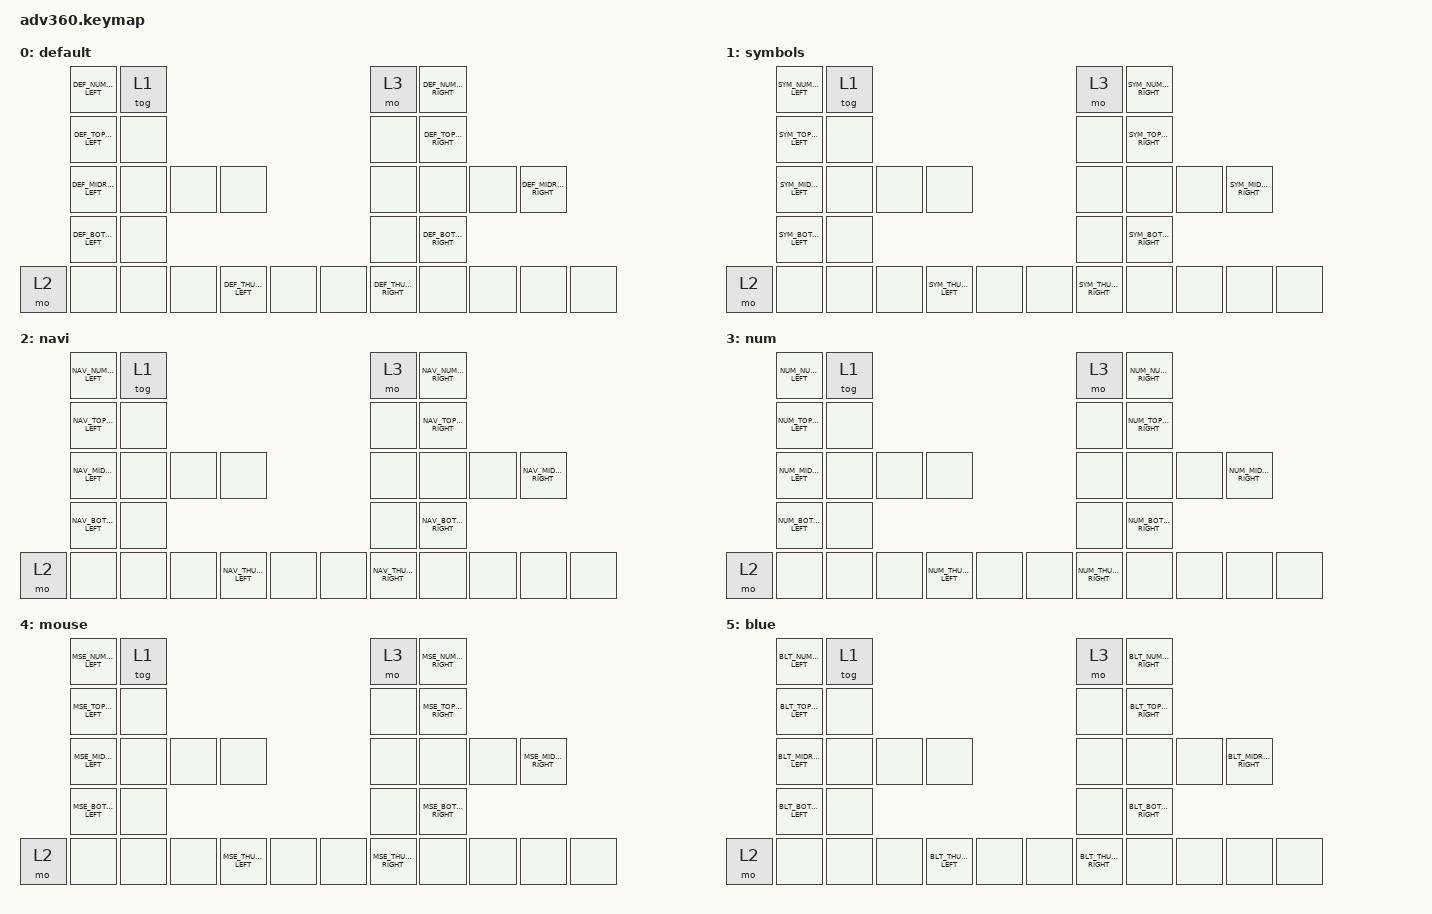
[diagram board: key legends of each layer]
#include "keys.h"                                      // key-position labels
#define KEYS_L LN0 LN1 LN2 LN3 LN4 LN5 \
               LT0 LT1 LT2 LT3 LT4 LT5 \
               LM0 LM1 LM2 LM3 LM4 LM5 \
               LB0 LB1 LB2 LB3 LB4 LB5
#define KEYS_R RN0 RN1 RN2 RN3 RN4 RN5 \
               RT0 RT1 RT2 RT3 RT4 RT5 \
               RM0 RM1 RM2 RM3 RM4 RM5 \
               RB0 RB1 RB2 RB3 RB4 RB5
#define THUMBS_L LHT0 LHT1 LHM0 LHB0 LHB1 LHB2
#define THUMBS_R RHT0 RHT1 RHM0 RHB0 RHB1 RHB2

#define THUMBS THUMBS_L THUMBS_R

#include "kbd_layout/keymap.h"

#include <behaviors.dtsi>
#include <dt-bindings/zmk/keys.h>
#include <dt-bindings/zmk/bt.h>
#include <dt-bindings/zmk/rgb.h>
#include <dt-bindings/zmk/stp.h>
#include <dt-bindings/zmk/backlight.h>
#include <dt-bindings/zmk/pointing.h>

/ {
    behaviors {
      #include "macros.dtsi"
      #include "version.dtsi"

      hm: homerow_mods {
          compatible = "zmk,behavior-hold-tap";
          label = "HOMEROW_MODS";
          #binding-cells = <2>;
          tapping-term-ms = <200>;
          quick_tap_ms = <175>;
          flavor = "tap-preferred";
          bindings = <&kp>, <&kp>;
      };
      lhm: left_homerow_mods {
          flavor = "balanced";
          tapping-term-ms = <500>;    // <---[[moderate duration]]
          quick-tap-ms = <0>;
          require-prior-idle-ms = <150>;
          compatible = "zmk,behavior-hold-tap";
          #binding-cells = <2>;
          bindings = <&kp>, <&kp>;
          hold-trigger-key-positions = <KEYS_R THUMBS>;
          hold-trigger-on-release;
      };
      rhm: right_homerow_mods {
          flavor = "balanced";
          tapping-term-ms = <500>;    // <---[[moderate duration]]
          quick-tap-ms = <0>;
          require-prior-idle-ms = <150>;
          compatible = "zmk,behavior-hold-tap";
          #binding-cells = <2>;
          bindings = <&kp>, <&kp>;
          hold-trigger-key-positions = <KEYS_L THUMBS>;
          hold-trigger-on-release;
      };
    };

  keymap {
    compatible = "zmk,keymap";

    default_layer {
      display-name = "default";
      bindings = <
         DEF_NUMROW_LEFT       &tog 1                           &mo 3 DEF_NUMROW_RIGHT
         DEF_TOPROW_LEFT       &none                            &none DEF_TOPROW_RIGHT
         DEF_MIDROW_LEFT       &none &none &none    &none &none &none DEF_MIDROW_RIGHT
         DEF_BOTROW_LEFT                   &none    &none             DEF_BOTROW_RIGHT
  &mo 2  &none &none &none DEF_THUMBS_LEFT &none    &none DEF_THUMBS_RIGHT &none &none &none &none
      >;
    };
    symbols {
      display-name = "symbols";
      bindings = <
         SYM_NUMROW_LEFT       &tog 1                           &mo 3 SYM_NUMROW_RIGHT
         SYM_TOPROW_LEFT       &none                            &none SYM_TOPROW_RIGHT
         SYM_MIDROW_LEFT       &none &none &none    &none &none &none SYM_MIDROW_RIGHT
         SYM_BOTROW_LEFT                   &none    &none             SYM_BOTROW_RIGHT
  &mo 2  &none &none &none SYM_THUMBS_LEFT &none    &none SYM_THUMBS_RIGHT &none &none &none &none
      >;
    };
    navigation {
      display-name = "navi";
      bindings = <
         NAV_NUMROW_LEFT       &tog 1                           &mo 3 NAV_NUMROW_RIGHT
         NAV_TOPROW_LEFT       &none                            &none NAV_TOPROW_RIGHT
         NAV_MIDROW_LEFT       &none &none &none    &none &none &none NAV_MIDROW_RIGHT
         NAV_BOTROW_LEFT                   &none    &none             NAV_BOTROW_RIGHT
  &mo 2  &none &none &none NAV_THUMBS_LEFT &none    &none NAV_THUMBS_RIGHT &none &none &none &none
      >;
    };
    numbers {
      display-name = "num";
      bindings = <
         NUM_NUMROW_LEFT       &tog 1                           &mo 3 NUM_NUMROW_RIGHT
         NUM_TOPROW_LEFT       &none                            &none NUM_TOPROW_RIGHT
         NUM_MIDROW_LEFT       &none &none &none    &none &none &none NUM_MIDROW_RIGHT
         NUM_BOTROW_LEFT                   &none    &none             NUM_BOTROW_RIGHT
  &mo 2  &none &none &none NUM_THUMBS_LEFT &none    &none NUM_THUMBS_RIGHT &none &none &none &none
      >;
    };
    mouse {
      display-name = "mouse";
      bindings = <
         MSE_NUMROW_LEFT       &tog 1                           &mo 3 MSE_NUMROW_RIGHT
         MSE_TOPROW_LEFT       &none                            &none MSE_TOPROW_RIGHT
         MSE_MIDROW_LEFT       &none &none &none    &none &none &none MSE_MIDROW_RIGHT
         MSE_BOTROW_LEFT                   &none    &none             MSE_BOTROW_RIGHT
  &mo 2  &none &none &none MSE_THUMBS_LEFT &none    &none MSE_THUMBS_RIGHT &none &none &none &none
      >;
    };
    bluetooth {
      display-name = "blue";
      bindings = <
         BLT_NUMROW_LEFT       &tog 1                           &mo 3 BLT_NUMROW_RIGHT
         BLT_TOPROW_LEFT       &none                            &none BLT_TOPROW_RIGHT
         BLT_MIDROW_LEFT       &none &none &none    &none &none &none BLT_MIDROW_RIGHT
         BLT_BOTROW_LEFT                   &none    &none             BLT_BOTROW_RIGHT
  &mo 2  &none &none &none BLT_THUMBS_LEFT &none    &none BLT_THUMBS_RIGHT &none &none &none &none
      >;
    };
  };
};
